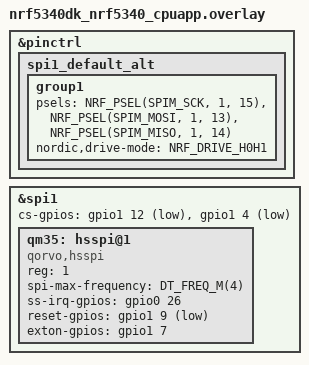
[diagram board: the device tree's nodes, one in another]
/*
 * Copyright (c) 2025 Nordic Semiconductor ASA
 *
 * SPDX-License-Identifier: LicenseRef-Nordic-5-Clause
 */

#include <zephyr/dt-bindings/gpio/nordic-nrf-gpio.h>

&pinctrl {
	spi1_default_alt: spi1_default_alt {
		group1 {
			psels = <NRF_PSEL(SPIM_SCK, 1, 15)>,
				<NRF_PSEL(SPIM_MOSI, 1, 13)>,
				<NRF_PSEL(SPIM_MISO, 1, 14)>;
			nordic,drive-mode = <NRF_DRIVE_H0H1>;
		};
	};
};

&spi1 {
	/* CS array: @0: NFC reader             @1: QM35 UWB module */
	cs-gpios = <&gpio1 12 GPIO_ACTIVE_LOW>,
		   <&gpio1 4 (GPIO_ACTIVE_LOW | NRF_GPIO_DRIVE_H0H1)>;

	qm35: hsspi@1 {
		status = "okay";
		compatible = "qorvo,hsspi";
		reg = <1>;
		spi-max-frequency = <DT_FREQ_M(4)>;
		ss-irq-gpios = <&gpio0 26 (GPIO_ACTIVE_HIGH | GPIO_PULL_DOWN)>;
		reset-gpios = <&gpio1 9 (GPIO_ACTIVE_LOW | GPIO_OPEN_DRAIN)>;
		exton-gpios = <&gpio1 7 GPIO_ACTIVE_HIGH>;
	};
};
